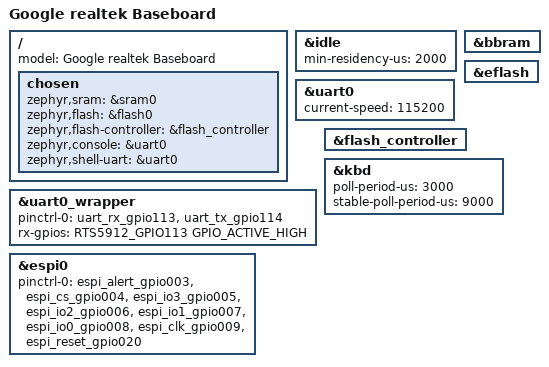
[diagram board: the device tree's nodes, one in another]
/* Copyright 2025 The ChromiumOS Authors
 * Use of this source code is governed by a BSD-style license that can be
 * found in the LICENSE file.
 */

#include <cros/realtek/realtek.dtsi>
#include <dt-bindings/gpio_defines.h>
#include <dt-bindings/gpio/realtek-gpio.h>
#include <realtek/ec/rts5912-pinctrl.dtsi>
#include <cros/vivaldi_kbd_default.dtsi>

#define GPIO_VOLTAGE_1P8 RTS5912_GPIO_VOLTAGE_1V8

/ {
	model = "Google realtek Baseboard";

	chosen {
		zephyr,sram = &sram0;
		zephyr,flash = &flash0;
		zephyr,flash-controller = &flash_controller;
		zephyr,console = &uart0;
		zephyr,shell-uart = &uart0;
	};
};

/* Entering and exiting heavy sleep on RTS5912/RTS5915 requires enabling and
 * locking the 100 MHz PLL and switching system clocks with interrupts masked,
 * and the RTMR driver subtracts 7 cycles (~213 us) on every timer reload. Set
 * min-residency-us to 2000 us so short 1 ms sleeps (k_msleep(1)) do not enter
 * heavy sleep and delay sysworkq/watchdog reloads, while preserving deep sleep
 * residency across longer idle intervals during S0ix.
 */
&idle {
	min-residency-us = <2000>;
};

&uart0 {
	status = "okay";
	current-speed = <115200>;
};

&uart0_wrapper {
	status = "okay";
	pinctrl-0 = <&uart_rx_gpio113 &uart_tx_gpio114>;
	pinctrl-names = "default";
	rx-gpios = <RTS5912_GPIO113 GPIO_ACTIVE_HIGH>;
};

&espi0 {
	pinctrl-0 = < &espi_alert_gpio003 &espi_cs_gpio004
				&espi_io3_gpio005 &espi_io2_gpio006
				&espi_io1_gpio007 &espi_io0_gpio008
				&espi_clk_gpio009 &espi_reset_gpio020>;
	pinctrl-names = "default";
};

&bbram {
	status = "okay";
};

&eflash {
	status = "okay";
};

&flash_controller {
	status = "okay";
};

&kbd {
        poll-period-us = <3000>;
        stable-poll-period-us = <9000>;
};
